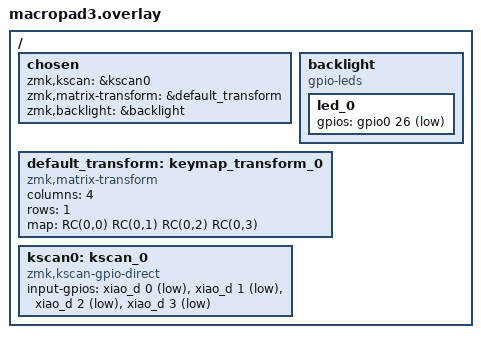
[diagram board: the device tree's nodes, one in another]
#include <dt-bindings/zmk/matrix_transform.h>

/ {
    chosen {
        zmk,kscan = &kscan0;
        zmk,matrix-transform = &default_transform;
        zmk,backlight = &backlight;
    };

    backlight: backlight {
        compatible = "gpio-leds";
        led_0 {
            gpios = <&gpio0 26 GPIO_ACTIVE_LOW>;
        };
    };

    default_transform: keymap_transform_0 {
        compatible = "zmk,matrix-transform";
        columns = <4>;
        rows = <1>;
        map = <
            RC(0,0) RC(0,1) RC(0,2) RC(0,3)
        >;
    };

    kscan0: kscan_0 {
        compatible = "zmk,kscan-gpio-direct";
        input-gpios
            = <&xiao_d 0 (GPIO_ACTIVE_LOW | GPIO_PULL_UP)> // D0: Ctrl + C
            , <&xiao_d 1 (GPIO_ACTIVE_LOW | GPIO_PULL_UP)> // D1: Ctrl + V
            , <&xiao_d 2 (GPIO_ACTIVE_LOW | GPIO_PULL_UP)> // D2: Alt + Tab
            , <&xiao_d 3 (GPIO_ACTIVE_LOW | GPIO_PULL_UP)> // D3: 截圖鍵
            ;
    };
};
